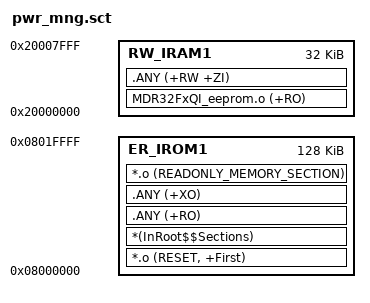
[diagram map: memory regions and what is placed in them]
; *************************************************************
; *** Scatter-Loading Description File generated by uVision ***
; *************************************************************

LR_IROM1 0x08000000 0x00020000  {    ; load region size_region
  ER_IROM1 0x08000000 0x00020000  {  ; load address = execution address
   *.o (RESET, +First)
   *(InRoot$$Sections)
   .ANY (+RO)
   .ANY (+XO)
   *.o (READONLY_MEMORY_SECTION)
  }
  RW_IRAM1 0x20000000 0x00008000  {  ; RW data
    MDR32FxQI_eeprom.o (+RO)
   .ANY (+RW +ZI)
  }
}

